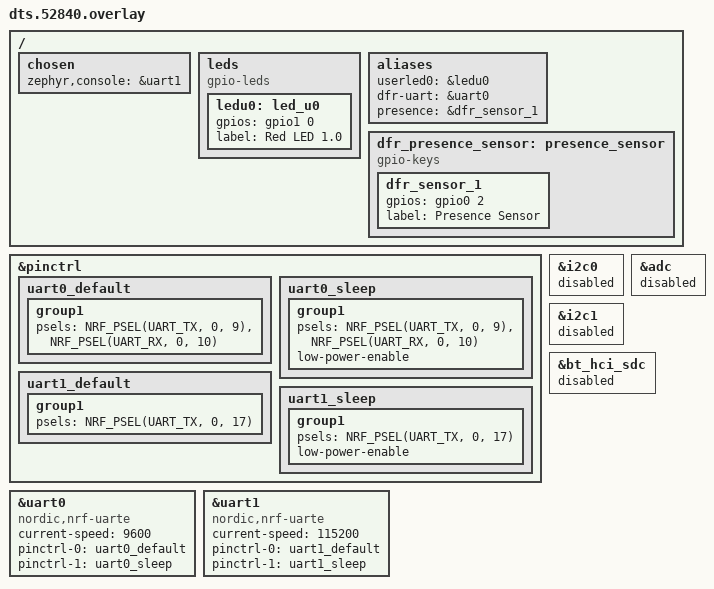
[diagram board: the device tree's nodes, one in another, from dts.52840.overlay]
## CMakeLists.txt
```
# SPDX-License-Identifier: Apache-2.0

cmake_minimum_required(VERSION 3.20.0)

set(EXTRA_DTC_OVERLAY_FILE "dts.overlay")

find_package(Zephyr REQUIRED HINTS $ENV{ZEPHYR_BASE})
project(presence_dfr_c4001)

target_include_directories(app PRIVATE submodules/esp_generic_lib/include)

target_sources(app PRIVATE src/main.cpp  src/c4001_task.cpp)
add_subdirectory(src/lib)

zephyr_include_directories(submodules/nrf_zb_cpp/include)
zephyr_include_directories(submodules/nrf_general/include)

include(cmake/CustomLibcxx.cmake)

if(COMMAND setup_custom_libcxx)
    setup_custom_libcxx(app)
else()
    target_link_libraries(app PRIVATE c stdc++ supc++)
    target_compile_options(app PRIVATE -fmacro-backtrace-limit=0)
    target_compile_options(app PRIVATE -D__cpp_concepts=202002L -Wno-builtin-macro-redefined -Wno-invalid-offsetof)
endif()
```

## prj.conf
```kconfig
#
# Copyright (c) 2020 Nordic Semiconductor ASA
#
# SPDX-License-Identifier: LicenseRef-Nordic-5-Clause
#
CONFIG_SERIAL=y
CONFIG_GPIO=y
CONFIG_SENSOR=y
CONFIG_UART_USE_RUNTIME_CONFIGURE=y
CONFIG_UART_NRFX_CUSTOM_BAUDRATE=y

CONFIG_UART_ASYNC_API=y
# CONFIG_UART_20_INTERRUPT_DRIVEN=y
# CONFIG_UART_20_ASYNC=n
CONFIG_UART_30_INTERRUPT_DRIVEN=n
CONFIG_UART_30_ASYNC=y

CONFIG_REBOOT=y
CONFIG_RAM_POWER_DOWN_LIBRARY=y
CONFIG_SETTINGS=y
CONFIG_REGULATOR=y
```

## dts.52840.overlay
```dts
/ {
	chosen {
		zephyr,console = &uart1;
	};

	leds {
		compatible = "gpio-leds";
		ledu0: led_u0 {
			gpios = <&gpio1 0 GPIO_ACTIVE_HIGH>;
			label = "Red LED 1.0";
		};
	};

	aliases{
		userled0 = &ledu0;
		dfr-uart = &uart0;
		presence = &dfr_sensor_1;
	};

    dfr_presence_sensor: presence_sensor {
		/* gpios = <&gpio1 5 (GPIO_ACTIVE_HIGH | GPIO_PULL_DOWN)>; */

		compatible = "gpio-keys";
		dfr_sensor_1: dfr_sensor_1{
			gpios = <&gpio0 2 (GPIO_ACTIVE_HIGH | GPIO_PULL_DOWN)>;
			label = "Presence Sensor";
		};
    };
};

&pinctrl {
	uart0_default: uart0_default {
		group1 {
			psels = <NRF_PSEL(UART_TX, 0, 9)>,
				<NRF_PSEL(UART_RX, 0, 10)>;
		};
	};

	uart0_sleep: uart0_sleep {
		group1 {
			psels = <NRF_PSEL(UART_TX, 0, 9)>,
				<NRF_PSEL(UART_RX, 0, 10)>;
			low-power-enable;
		};
	};
	uart1_default: uart1_default {
		group1 {
			psels = <NRF_PSEL(UART_TX, 0, 17)>;
		};
	};

	uart1_sleep: uart1_sleep {
		group1 {
			psels = <NRF_PSEL(UART_TX, 0, 17)>;
			low-power-enable;
		};
	};
};

&uart0 {
	compatible = "nordic,nrf-uarte";
	status = "okay";
	current-speed = <9600>;
	pinctrl-0 = <&uart0_default>;
	pinctrl-1 = <&uart0_sleep>;
	pinctrl-names = "default", "sleep";
};

&uart1 {
	compatible = "nordic,nrf-uarte";
	status = "okay";
	current-speed = <115200>;
	pinctrl-0 = <&uart1_default>;
	pinctrl-1 = <&uart1_sleep>;
	pinctrl-names = "default", "sleep";
};

&i2c0 {
    status = "disabled";
};
&adc {
    status = "disabled";
};

&i2c1 {
    status = "disabled";
};
&bt_hci_sdc {
    status = "disabled";
};
```

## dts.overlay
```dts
/ {
	chosen {
		ncs,zigbee-timer = &timer20;
		zephyr,console = &uart20;
	};

	leds {
		compatible = "gpio-leds";
		led0: led_0 {
			gpios = <&gpio2 9 GPIO_ACTIVE_HIGH>;
			label = "Red LED 0";
		};
	};

	aliases {
		userled0 = &led0;
		presence = &dfr_sensor_1;
		dfr-uart = &uart30;
	};

	/* A standalone node describing your hardware */
    dfr_presence_sensor: presence_sensor {
		/* gpios = <&gpio1 5 (GPIO_ACTIVE_HIGH | GPIO_PULL_DOWN)>; */

		compatible = "gpio-keys";
		dfr_sensor_1: dfr_sensor_1{
			gpios = <&gpio1 5 (GPIO_ACTIVE_HIGH | GPIO_PULL_DOWN)>;
			label = "Presence Sensor";
		};
    };
};

// restore full RRAM and SRAM space - by default some parts are dedicated to FLRP
//&cpuapp_rram {
//	reg = <0x0 DT_SIZE_K(1524)>;
//};
//
//&cpuapp_sram {
//	reg = <0x20000000 DT_SIZE_K(256)>;
//	ranges = <0x0 0x20000000  0x40000>;
//};

&pinctrl {
	/omit-if-no-ref/ uart20_default: uart20_default {
		group1 {
			psels = <NRF_PSEL(UART_TX, 1, 7)>;
		};
	};

	/omit-if-no-ref/ uart20_sleep: uart20_sleep {
		group1 {
			psels = <NRF_PSEL(UART_TX, 1, 7)>;
			low-power-enable;
		};
	};
	/* /omit-if-no-ref/ uart22_default: uart22_default { */
	/* 	group1 { */
	/* 		psels = <NRF_PSEL(UART_RX, 1, 6)>; */
	/* 	}; */
	/* }; */

	/* /omit-if-no-ref/ uart22_sleep: uart22_sleep { */
	/* 	group1 { */
	/* 		psels = <NRF_PSEL(UART_RX, 1, 6)>; */
	/* 		low-power-enable; */
	/* 	}; */
	/* }; */
	/omit-if-no-ref/ uart30_default: uart30_default {
		group1 {
			psels = <NRF_PSEL(UART_TX, 0, 1)>, <NRF_PSEL(UART_RX, 0, 2)>;
		};
	};

	/omit-if-no-ref/ uart30_sleep: uart30_sleep {
		group1 {
			psels = <NRF_PSEL(UART_TX, 0, 1)>, <NRF_PSEL(UART_RX, 0, 2)>;
			low-power-enable;
		};
	};
};


&timer20 {
	status = "okay";
};

&uart20 {
	status = "okay";
	current-speed = <115200>;
	/* pinctrl-0 = <&uart20_default>; */
	/* pinctrl-1 = <&uart20_sleep>; */
	/* pinctrl-names = "default", "sleep"; */
};
/* &uart22 { */
/* 	status = "okay"; */
/* 	current-speed = <115200>; */
/* 	pinctrl-0 = <&uart22_default>; */
/* 	pinctrl-1 = <&uart22_sleep>; */
/* 	pinctrl-names = "default", "sleep"; */
/* }; */
&uart30 {
	status = "okay";
	current-speed = <9600>;
	pinctrl-0 = <&uart30_default>;
	pinctrl-1 = <&uart30_sleep>;
	pinctrl-names = "default", "sleep";
};
&gpio2 {
	status = "okay";
};
```

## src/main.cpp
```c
/*
 * Copyright (c) 2023, Meta
 *
 * SPDX-License-Identifier: Apache-2.0
 */

#define FORCE_FMT
#define PRINTF_FUNC(...) printk(__VA_ARGS__)

#include <zephyr/kernel.h>
#include <zephyr/drivers/gpio.h>
#include <zephyr/settings/settings.h>
#include "c4001_task.hpp"

/**********************************************************************/
/* Zigbee                                                             */
/**********************************************************************/
#include <nrfzbcpp/zb_main.hpp>
#include <nrfzbcpp/zb_std_cluster_desc.hpp>
#include <nrfzbcpp/zb_status_cluster_desc.hpp>
#include <nrfzbcpp/zb_occupancy_sensing_cluster_desc.hpp>
#include "zb/zb_c4001_cluster_desc.hpp"

/**********************************************************************/
/* Zigbee Declarations and Definitions                                */
/**********************************************************************/
static bool g_ZigbeeReady = false;

/* Manufacturer name (32 bytes). */
#define INIT_BASIC_MANUF_NAME      "SFINAE"

/* Model number assigned by manufacturer (32-bytes long string). */
#define INIT_BASIC_MODEL_ID        "C4001-NG"
//#define INIT_SW_VER                "C4001-1.0"


/* Button used to enter the Bulb into the Identify mode. */
#define IDENTIFY_MODE_BUTTON            DK_BTN1_MSK

/* Button to start Factory Reset */
#define FACTORY_RESET_BUTTON IDENTIFY_MODE_BUTTON

/* Device endpoint, used to receive light controlling commands. */
constexpr uint8_t kMMW_EP = 1;
constexpr uint16_t kDEV_ID = 0xBAAD;

struct device_ctx_t{
    zb::zb_zcl_basic_names_t basic_attr;
    zb::zb_zcl_status_t status_attr;
    zb::zb_zcl_occupancy_pir_and_ultrasonic_t occupancy;
    zb::zb_zcl_on_off_attrs_client_t on_off_client;
    zb::zb_zcl_c4001_t c4001;
};

//attribute shortcuts for template arguments

/**********************************************************************/
/* Status attribute shortcuts                                         */
/**********************************************************************/
constexpr auto kAttrStatus1 = &zb::zb_zcl_status_t::status1;
constexpr auto kAttrStatus2 = &zb::zb_zcl_status_t::status2;
constexpr auto kAttrStatus3 = &zb::zb_zcl_status_t::status3;

/**********************************************************************/
/* C4001 attributes                                                   */
/**********************************************************************/
constexpr auto kAttrRMin = &zb::zb_zcl_c4001_t::range_min;
constexpr auto kAttrRMax = &zb::zb_zcl_c4001_t::range_max;
constexpr auto kAttrRTrig = &zb::zb_zcl_c4001_t::range_trig;
constexpr auto kAttrInhibitDuration = &zb::zb_zcl_c4001_t::inhibit_duration;
constexpr auto kAttrSTrig = &zb::zb_zcl_c4001_t::sensitivity_detect;
constexpr auto kAttrSHold = &zb::zb_zcl_c4001_t::sensitivity_hold;

/**********************************************************************/
/* Occupancy attribute shortcuts                                      */
/**********************************************************************/
constexpr auto kAttrOccupancy = &zb::zb_zcl_occupancy_ultrasonic_t::occupancy;
constexpr auto kAttrDetectToClearDelay = &zb::zb_zcl_c4001_t::clear_delay; //&zb::zb_zcl_occupancy_ultrasonic_t::UltrasonicOccupiedToUnoccupiedDelay;
constexpr auto kAttrClearToDetectDelay = &zb::zb_zcl_c4001_t::detect_delay;//&zb::zb_zcl_occupancy_ultrasonic_t::UltrasonicUnoccupiedToOccupiedDelay;

constexpr auto kCmdOn = &zb::zb_zcl_on_off_attrs_client_t::on;
constexpr auto kCmdOff = &zb::zb_zcl_on_off_attrs_client_t::off;

zb::CmdHandlingResult on_cmd_restart();

/* Zigbee device application context storage. */
static constinit device_ctx_t dev_ctx{
    .basic_attr = {
	{
	    .zcl_version = ZB_ZCL_VERSION,
	    .power_source = zb::zb_zcl_basic_min_t::PowerSource::DC,
	},
	/*.manufacturer =*/ INIT_BASIC_MANUF_NAME,
	/*.model =*/ INIT_BASIC_MODEL_ID,
    },
    .c4001{
	.cmd_restart = {.cb = on_cmd_restart}
    }
};

constinit static auto zb_ctx = zb::make_device(
	zb::make_ep_args<{.ep=kMMW_EP, .dev_id=kDEV_ID, .dev_ver=1}>(
	    dev_ctx.basic_attr
	    , dev_ctx.status_attr
	    , dev_ctx.occupancy
	    , dev_ctx.c4001
	    , dev_ctx.on_off_client
	    )
	);

/**********************************************************************/
/* Defining access to the global zigbee device context                */
/**********************************************************************/
//needed for proper command handling
struct zb::global_device
{
    static auto& get() { return zb_ctx; }
};

//a shortcut for a convenient access
constinit static auto &zb_ep = zb_ctx.ep<kMMW_EP>();

/**********************************************************************/
/* Device defines                                                     */
/**********************************************************************/
/* The devicetree node identifier for the "led0" alias. */
#define LED0_NODE DT_ALIAS(led0)

/*
 * A build error on this line means your board is unsupported.
 * See the sample documentation for information on how to fix this.
 */
static const struct gpio_dt_spec led = GPIO_DT_SPEC_GET(LED0_NODE, gpios);
//constinit const struct device *rd_uart = DEVICE_DT_GET(DT_NODELABEL(uart30));

///* Get the node from the alias */
#define SENSOR_NODE DT_ALIAS(presence)

constinit static dfr::C4001 *pC4001 = nullptr;

/* Get the GPIO spec directly from the node */
/* Note: We look for the property "gpios" inside the node */
static const struct gpio_dt_spec presence = GPIO_DT_SPEC_GET(SENSOR_NODE, gpios);

void send_on_off(uint8_t val);

gpio_callback g_cb;

void presence_triggered(const struct device *port,
					struct gpio_callback *cb,
					gpio_port_pins_t pins)
{
    int val = gpio_pin_get_dt(&presence);
    //TODO: remove me
    gpio_pin_set_dt(&led, val);

    if (g_ZigbeeReady) //post to zigbee and shoot commands
	zb_schedule_app_callback(&send_on_off, val);
    else
    {
	//write latest state directly
	dev_ctx.occupancy.occupancy = val;
    }
}
zb::CmdHandlingResult on_cmd_restart()
{
    printk("c4001::restart\r\n");
    c4001::restart();
    return {};
}

void send_on_off(uint8_t val)
{
    zb_ep.attr<kAttrOccupancy>() = val == 1;
    if (val == 1)
	zb_ep.send_cmd<kCmdOn>();
    else
	zb_ep.send_cmd<kCmdOff>();
}

void on_dev_cb_error(int err)
{
    printk("on_dev_cb_error: %d\r\n", err);
}

void zb_c4001_update(uint8_t e)
{
    using namespace c4001; 
    cfg_id_t id = (cfg_id_t)e;
    if (id & cfg_id_t::Range)
    {
	zb_ep.attr<kAttrRMin>() = pC4001->GetRangeFrom();
	zb_ep.attr<kAttrRMax>() = pC4001->GetRangeTo();
    }
    if (id & cfg_id_t::RangeTrig)
    {
	zb_ep.attr<kAttrRTrig>() = pC4001->GetTriggerDistance();
    }
    if (id & cfg_id_t::Delay)
    {
	zb_ep.attr<kAttrClearToDetectDelay>() = pC4001->GetDetectLatency();
	zb_ep.attr<kAttrDetectToClearDelay>() = pC4001->GetClearLatency();
    }
    if (id & cfg_id_t::InhibitDuration)
    {
	zb_ep.attr<kAttrInhibitDuration>() = pC4001->GetInhibitDuration();
    }
    if (id & cfg_id_t::Sensitivity)
    {
	zb_ep.attr<kAttrSTrig>() = pC4001->GetSensitivityTrig();
	zb_ep.attr<kAttrSHold>() = pC4001->GetSensitivityHold();
    }
}

void zb_c4001_error(uint8_t e)
{
    using namespace c4001;
    //generally: set zb attributes to current values
    switch(err_t(e))
    {
	case err_t::Range:
	    zb_c4001_update((uint8_t)cfg_id_t::Range);
	    break;
	case err_t::RangeTrig:
	    zb_c4001_update((uint8_t)cfg_id_t::RangeTrig);
	    break;
	case err_t::Delay:
	    zb_c4001_update((uint8_t)cfg_id_t::Delay);
	    break;
	case err_t::InhibitDuration:
	    zb_c4001_update((uint8_t)cfg_id_t::InhibitDuration);
	    break;
	case err_t::Sensitivity:
	    zb_c4001_update((uint8_t)cfg_id_t::Sensitivity);
	    break;
	default:
	break;
    }
    zb_ep.attr<kAttrStatus1>() = e;
}

void on_c4001_error(c4001::err_t e)
{
    if (g_ZigbeeReady)
	zb_schedule_app_callback(&zb_c4001_error, (uint8_t)e);
}

void on_c4001_upd(c4001::cfg_id_t id)
{
    if (g_ZigbeeReady)
	zb_schedule_app_callback(&zb_c4001_update, (uint8_t)id);
}

void on_uto_delay_changed(uint16_t d)
{
    c4001::set_detect_delay(d);
}

void on_otu_delay_changed(uint16_t d)
{
    c4001::set_clear_delay(d);
}


int configure_c4001_out_pin();

void on_zigbee_start()
{
    printk("on_zigbee_start\r\n");
    g_ZigbeeReady = true;
    //TODO: stuff...
}

/**@brief Zigbee stack event handler.
 *
 * @param[in]   bufid   Reference to the Zigbee stack buffer
 *                      used to pass signal.
 */
void zboss_signal_handler(zb_bufid_t bufid)
{
        zb_zdo_app_signal_hdr_t *pHdr;
        auto signalId = zb_get_app_signal(bufid, &pHdr);

	auto ret = zb::tpl_signal_handler<zb::sig_handlers_t{
	.on_leave = +[]{ 
	    k_sleep(K_MSEC(2100));
	    sys_reboot(SYS_REBOOT_COLD);
	},
	    //.on_error = []{ led::show_pattern(led::kPATTERN_3_BLIPS_NORMED, 1000); },
	    .on_dev_reboot = on_zigbee_start,
	    .on_steering = on_zigbee_start,
	   }>(bufid);
    const uint32_t LOCAL_ERR_CODE = (uint32_t) (-ret);	
    if (LOCAL_ERR_CODE != RET_OK) {				
	zb_osif_abort();				
    }							
}

int main(void)
{
    int err = settings_subsys_init();
    err = settings_load();

    pC4001 = c4001::setup(&on_c4001_error, &on_c4001_upd);
    if (pC4001)
    {
	dev_ctx.c4001.range_min = pC4001->GetRangeFrom();
	dev_ctx.c4001.range_max = pC4001->GetRangeTo();
	dev_ctx.c4001.range_trig = pC4001->GetTriggerDistance();
	dev_ctx.c4001.inhibit_duration = pC4001->GetInhibitDuration();
	dev_ctx.c4001.sensitivity_detect = pC4001->GetSensitivityTrig();
	dev_ctx.c4001.sensitivity_hold = pC4001->GetSensitivityHold();
	dev_ctx.c4001.sw_ver = pC4001->GetSWVer().m_Version;
	dev_ctx.c4001.hw_ver = pC4001->GetHWVer().m_Version;
    }

    /* Register callback for handling ZCL commands. */
    auto dev_cb = zb::tpl_device_cb<
	zb::dev_cb_handlers_desc{ .error_handler = on_dev_cb_error }
	, zb::handle_set_for<kAttrDetectToClearDelay, c4001::set_clear_delay>(zb_ep)
	, zb::handle_set_for<kAttrClearToDetectDelay, c4001::set_detect_delay>(zb_ep)
	, zb::handle_set_for<kAttrRMin,               c4001::set_range_from>(zb_ep)
	, zb::handle_set_for<kAttrRMax,               c4001::set_range_to>(zb_ep)
	, zb::handle_set_for<kAttrRTrig,              c4001::set_range_trig>(zb_ep)
	, zb::handle_set_for<kAttrInhibitDuration,    c4001::set_inhibit_duration>(zb_ep)
	, zb::handle_set_for<kAttrSTrig,              c4001::set_detect_sensitivity>(zb_ep)
	, zb::handle_set_for<kAttrSHold,              c4001::set_hold_sensitivity>(zb_ep)
    >;

    ZB_ZCL_REGISTER_DEVICE_CB(dev_cb);

    /* Register device context (endpoints). */
    ZB_AF_REGISTER_DEVICE_CTX(zb_ctx);

    if (int err = configure_c4001_out_pin(); err != 0)
    {
	printk("Failed to configure c4001 out pin\r\n");
    }
    {
	int val = gpio_pin_get_dt(&presence);
	printk("Presence pin state: %d\r\n", val);
	dev_ctx.occupancy.occupancy = val;
    }
    zigbee_enable();

    printk("Main: sleep forever\r\n");
    {
	printk("C4001; HW=%s\r\n", pC4001->GetHWVer().m_Version);
	printk("C4001; SW=%s\r\n", pC4001->GetSWVer().m_Version);
	printk("C4001; Range=%.1f to %.1fm\r\n", (double)pC4001->GetRangeFrom(), (double)pC4001->GetRangeTo());
	printk("C4001; Latency; to detect=%.1fs; to clear=%.1fs\r\n", (double)pC4001->GetDetectLatency(), (double)pC4001->GetClearLatency());
	printk("C4001; Trig Range=%.1fm\r\n", (double)pC4001->GetTriggerDistance());
	printk("C4001; Sensitivity Detect=%d; Hold=%d;\r\n", pC4001->GetSensitivityTrig(), pC4001->GetSensitivityHold());
	printk("C4001; Inhibut Duration=%.1fs\r\n", (double)pC4001->GetInhibitDuration());
    }
    while (1) {
	k_sleep(K_FOREVER);
    }

    return 0;
}

int configure_c4001_out_pin()
{
    gpio_pin_configure_dt(&led, GPIO_OUTPUT_ACTIVE);
    int err = gpio_pin_configure_dt(&presence, GPIO_INPUT);
    if (err != 0)
    {
	printk("gpio_pin_configure_dt: %d\r\n", err);
	return err;
    }
    gpio_pin_set_dt(&led, 0);

    err = gpio_pin_interrupt_configure_dt(&presence, GPIO_INT_EDGE_BOTH);
    if (err != 0)
    {
	printk("gpio_pin_interrupt_configure_dt: %d\r\n", err);
	return err;
    }
    gpio_init_callback(&g_cb, presence_triggered, BIT(presence.pin));
    return gpio_add_callback_dt(&presence, &g_cb);
}
```

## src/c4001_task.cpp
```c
#define FORCE_FMT
#define PRINTF_FUNC(...) printk(__VA_ARGS__)

#include <zephyr/kernel.h>
#include <zephyr/drivers/gpio.h>
#include "c4001_task.hpp"
#include <variant>

#include <nrf_general/lib_msgq_typed.hpp>


namespace c4001
{
    namespace{
	template<class... O>
	struct overloaded:O...
	{
	    using O::operator()...;
	};
	template<class... O>
	overloaded(O... o)->overloaded<O...>;
    };
    constinit const struct device *c4001_uart = DEVICE_DT_GET(DT_NODELABEL(uart30));
    static dfr::C4001 c4001(c4001_uart);

    /**********************************************************************/
    /* Message Queue definitions + commands                               */
    /**********************************************************************/
    struct range_t
    {
	float from;
	float to;
    };
    struct range_trig_t
    {
	float trig;
    };
    struct delay_t
    {
	float detect;
	float clear;
    };
    struct sensitivity_t
    {
	uint8_t detect;
	uint8_t hold;
    };
    struct inhibit_duration_t
    {
	float duration;
    };
    struct save_cfg_t{};
    struct reset_cfg_t{};
    struct restart_cfg_t{};
    struct reload_cfg_t{};

    using QueueItem = std::variant<
			      range_t
			    , range_trig_t
			    , delay_t
			    , sensitivity_t
			    , inhibit_duration_t
			    , save_cfg_t
			    , reset_cfg_t
			    , restart_cfg_t
			    , reload_cfg_t
			>;

    using C4001Q = msgq::Queue<QueueItem,4>;
    K_MSGQ_DEFINE_TYPED(C4001Q, c4001q);

    void c4001_thread_entry(void *, void *, void *);
    constexpr size_t C4001_THREAD_STACK_SIZE = 1024 * 2;
    constexpr size_t C4001_THREAD_PRIORITY=7;

K_THREAD_DEFINE(c4001_thread, C4001_THREAD_STACK_SIZE,
	c4001_thread_entry, NULL, NULL, NULL,
	C4001_THREAD_PRIORITY, 0, -1);

    constinit err_callback_t g_err = nullptr;
    constinit upd_callback_t g_upd = nullptr;
    dfr::C4001* setup(err_callback_t err, upd_callback_t upd)
    {
	auto r = c4001.Init();
	if (!r)
	    return nullptr;
	g_err = err;
	g_upd = upd;
	k_thread_start(c4001_thread);
	return &c4001;
    }

    void set_range(float from, float to)
    {
	c4001q << range_t{.from = from, .to = to};
    }

    void set_range_from(float v)
    {
	c4001q << range_t{.from = v, .to = c4001.GetRangeTo()};
    }

    void set_range_to(float v)
    {
	c4001q << range_t{.from = c4001.GetRangeFrom(), .to = v};
    }

    void set_range_trig(float trig)
    {
	c4001q << range_trig_t{.trig = trig};
    }

    void set_detect_delay(float v)
    {
	c4001q << delay_t{.detect = v, .clear = c4001.GetClearLatency()};
    }

    void set_clear_delay(float v)
    {
	c4001q << delay_t{.detect = c4001.GetDetectLatency(), .clear = v};
    }

    void set_detect_clear_delay(float detect, float clear)
    {
	c4001q << delay_t{.detect = detect, .clear = clear};
    }

    void set_detect_sensitivity(uint8_t s)
    {
	c4001q << sensitivity_t{.detect = s, .hold = 255};
    }

    void set_hold_sensitivity(uint8_t s)
    {
	c4001q << sensitivity_t{.detect = 255, .hold = s};
    }

    void set_sensitivity(uint8_t detect, uint8_t hold)
    {
	c4001q << sensitivity_t{.detect = detect, .hold = hold};
    }

    void set_inhibit_duration(float dur)
    {
	c4001q << inhibit_duration_t{.duration = dur};
    }

    void save_config()
    {
	c4001q << save_cfg_t{};
    }

    void reset_config()
    {
	c4001q << reset_cfg_t{};
    }

    void restart()
    {
	c4001q << restart_cfg_t{};
    }

    void c4001_thread_entry(void *, void *, void *)
    {
	QueueItem q;
	using Cfg = dfr::C4001::Configurator;
	while(1)
	{
	    c4001q >> q;
	    std::visit(
		overloaded{
		    [](range_t const& v){ 
			if (auto r = c4001
				.GetConfigurator()
				.SetRange(v.from, v.to)
				.and_then([](Cfg &cfg){ return cfg.SaveConfig(); })
				.and_then([](Cfg &cfg){ return cfg.UpdateRange(); }); !r)
			{
			    if (g_err) g_err(err_t::Range);
			}
			else if (g_upd)
			    g_upd(cfg_id_t::Range);
		    }
		    ,[](range_trig_t const& v){  
			if (auto r = c4001
				.GetConfigurator()
				.SetTrigRange(v.trig)
				.and_then([](Cfg &cfg){ return cfg.SaveConfig(); })
				.and_then([](Cfg &cfg){ return cfg.UpdateTrigRange(); }); !r)
			{
			    if (g_err) g_err(err_t::RangeTrig);
			}
			else if (g_upd)
			    g_upd(cfg_id_t::RangeTrig);
		    }
		    ,[](delay_t const& v){  
			if (auto r = c4001
				.GetConfigurator()
				.SetLatency(v.detect, v.clear)
				.and_then([](Cfg &cfg){ return cfg.SaveConfig(); })
				.and_then([](Cfg &cfg){ return cfg.UpdateLatency(); }); !r)
			{
			    if (g_err) g_err(err_t::Delay);
			}
			else if (g_upd)
			    g_upd(cfg_id_t::Delay);
		    }
		    ,[](sensitivity_t const& v){  
			if (auto r = c4001
				.GetConfigurator()
				.SetSensitivity(v.detect, v.hold)
				.and_then([](Cfg &cfg){ return cfg.SaveConfig(); })
				.and_then([](Cfg &cfg){ return cfg.UpdateSensitivity(); }); !r)
			{
			    if (g_err) g_err(err_t::Sensitivity);
			}
			else if (g_upd)
			    g_upd(cfg_id_t::Sensitivity);
		    }
		    ,[](inhibit_duration_t const& v){  
			if (auto r = c4001
				.GetConfigurator()
				.SetInhibit(v.duration)
				.and_then([](Cfg &cfg){ return cfg.SaveConfig(); })
				.and_then([](Cfg &cfg){ return cfg.UpdateInhibit(); }); !r)
			{
			    if (g_err) g_err(err_t::InhibitDuration);
			}
			else if (g_upd)
			    g_upd(cfg_id_t::InhibitDuration);
		    }
		    ,[](save_cfg_t const& v){  
			if (auto r = c4001
				.GetConfigurator()
				.SaveConfig(); !r && g_err)
			    g_err(err_t::SaveConfig);
		    }
		    ,[](reset_cfg_t const& v){  
			if (auto r = c4001
				.GetConfigurator()
				.ResetConfig(); !r)
			{
			    if (g_err) g_err(err_t::ResetConfig);
			}
			else if (g_upd)
			    g_upd(cfg_id_t::All);
		    }
		    ,[](restart_cfg_t const& v){  
			if (auto r = c4001
				.GetConfigurator()
				.Restart(); !r)
			{
			    if (g_err) g_err(err_t::Restart);
			}
			else if (g_upd)
			    g_upd(cfg_id_t::All);
		    }
		    ,[](reload_cfg_t const& v){  
			if (auto r = c4001
				.GetConfigurator()
				.ReloadConfig(); !r)
			{
			    if (g_err) g_err(err_t::ReloadConfig);
			}
			else if (g_upd)
			    g_upd(cfg_id_t::All);
		    }
		},
		q
	    );
	}
    }
}
```

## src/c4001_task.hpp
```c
#ifndef C4001_TASK_HPP_
#define C4001_TASK_HPP_
#include "lib/lib_dfr_c4001.h"
#include <utility>

namespace c4001
{
    enum class cfg_id_t: uint8_t
    {
        Range           = 1 << 0,
        RangeTrig       = 1 << 1,
        Delay           = 1 << 2,
        Sensitivity     = 1 << 3,
        InhibitDuration = 1 << 4,
        All = Range | RangeTrig | Delay | Sensitivity | InhibitDuration,
    };
    constexpr bool operator&(cfg_id_t i1, cfg_id_t i2) { return (std::to_underlying(i1) & std::to_underlying(i2)) != 0; }

    enum class err_t
    {
        Ok,
        Range,
        RangeTrig,
        Delay,
        Sensitivity,
        InhibitDuration,
        SaveConfig,
        ResetConfig,
        Restart,
        ReloadConfig,
    };
    using err_callback_t = void(*)(err_t);
    using upd_callback_t = void(*)(cfg_id_t);
    dfr::C4001* setup(err_callback_t err, upd_callback_t upd);

    void set_range(float from, float to);
    void set_range_trig(float trig);
    void set_detect_delay(float v);
    void set_clear_delay(float v);
    void set_detect_clear_delay(float detect, float clear);
    void set_detect_sensitivity(uint8_t s);
    void set_hold_sensitivity(uint8_t s);
    void set_sensitivity(uint8_t detect, uint8_t hold);
    void set_inhibit_duration(float dur);
    void save_config();
    void reset_config();
    void restart();
}

#endif
```
